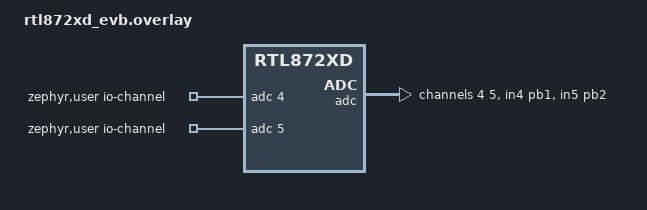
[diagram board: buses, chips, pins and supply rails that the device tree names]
/*
 * Copyright (c) 2024 Realtek Semiconductor Corp.
 *
 * SPDX-License-Identifier: Apache-2.0
 */

/ {
	zephyr,user {
		io-channels = <&adc 4>, <&adc 5>;

	};
};

&adc {
	pinctrl-0 = <&adc_in4_pb1 &adc_in5_pb2>;
	#address-cells = <1>;
	#size-cells = <0>;

	channel@4 {
		reg = <4>;
		zephyr,gain = "ADC_GAIN_1";
		zephyr,reference = "ADC_REF_INTERNAL";
		zephyr,acquisition-time = <ADC_ACQ_TIME_MAX>;
		zephyr,resolution = <12>;
	};

	channel@5 {
		reg = <5>;
		zephyr,gain = "ADC_GAIN_1";
		zephyr,reference = "ADC_REF_INTERNAL";
		zephyr,acquisition-time = <ADC_ACQ_TIME_MAX>;
		zephyr,resolution = <12>;
	};
};

